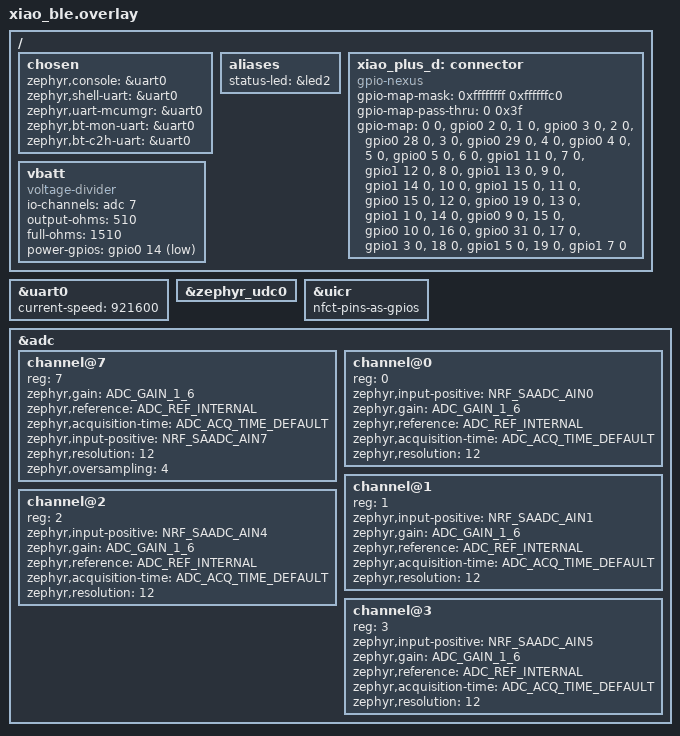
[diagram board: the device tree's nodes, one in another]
/ {
    chosen {
        zephyr,console = &uart0;
        zephyr,shell-uart = &uart0;
        zephyr,uart-mcumgr = &uart0;
        zephyr,bt-mon-uart = &uart0;
        zephyr,bt-c2h-uart = &uart0;
    };

    aliases {
        status-led = &led2;
    };
};

&uart0 {
    current-speed = <921600>;
};

&zephyr_udc0 {
    /delete-node/ board_cdc_acm_uart;
};

&uicr {
    nfct-pins-as-gpios;
};

/ {
    xiao_plus_d: connector {
        compatible = "gpio-nexus";
        #gpio-cells = <2>;
        gpio-map-mask = <0xffffffff 0xffffffc0>;
        gpio-map-pass-thru = <0 0x3f>;
        gpio-map = <0 0 &gpio0 2 0>, /* D0 */
            <1 0 &gpio0 3 0>,        /* D1 */
            <2 0 &gpio0 28 0>,       /* D2 */
            <3 0 &gpio0 29 0>,       /* D3 */
            <4 0 &gpio0 4 0>,        /* D4 */
            <5 0 &gpio0 5 0>,        /* D5 */
            <6 0 &gpio1 11 0>,       /* D6 */
            <7 0 &gpio1 12 0>,       /* D7 */
            <8 0 &gpio1 13 0>,       /* D8 */
            <9 0 &gpio1 14 0>,       /* D9 */
            <10 0 &gpio1 15 0>,      /* D10 */
            <11 0 &gpio0 15 0>,      /* D0.5 */
            <12 0 &gpio0 19 0>,      /* D1.5 */
            <13 0 &gpio1 1 0>,       /* D2.5 */
            <14 0 &gpio0 9 0>,       /* D3.5 */
            <15 0 &gpio0 10 0>,      /* D4.5 */
            <16 0 &gpio0 31 0>,      /* D5.5 */
            <17 0 &gpio1 3 0>,       /* D7.5 */
            <18 0 &gpio1 5 0>,       /* D8.5 */
            <19 0 &gpio1 7 0>;       /* D9.5 */
    };
};

#include <zephyr/dt-bindings/adc/adc.h>
#include <zephyr/dt-bindings/adc/nrf-saadc.h>

/ {
    vbatt {
        compatible = "voltage-divider";
        io-channels = <&adc 7>;
        output-ohms = <510>;
        full-ohms = <1510>;
        power-gpios = <&gpio0 14 (GPIO_ACTIVE_LOW | GPIO_OPEN_DRAIN)>;
    };
};

&adc {
    #address-cells = <1>;
    #size-cells = <0>;

    channel@7 {
        reg = <7>;
        zephyr,gain = "ADC_GAIN_1_6";
        zephyr,reference = "ADC_REF_INTERNAL";
        zephyr,acquisition-time = <ADC_ACQ_TIME_DEFAULT>;
        zephyr,input-positive = <NRF_SAADC_AIN7>;
        zephyr,resolution = <12>;
        zephyr,oversampling = <4>;
    };

    channel@0 {
        reg = <0>;

        /* P0.02 (AIN0) */
        zephyr,input-positive = <NRF_SAADC_AIN0>;

        zephyr,gain = "ADC_GAIN_1_6";
        zephyr,reference = "ADC_REF_INTERNAL";
        zephyr,acquisition-time = <ADC_ACQ_TIME_DEFAULT>;
        zephyr,resolution = <12>;
    };

    channel@1 {
        reg = <1>;

        /* P0.03 (AIN1) */
        zephyr,input-positive = <NRF_SAADC_AIN1>;

        zephyr,gain = "ADC_GAIN_1_6";
        zephyr,reference = "ADC_REF_INTERNAL";
        zephyr,acquisition-time = <ADC_ACQ_TIME_DEFAULT>;
        zephyr,resolution = <12>;
    };

    channel@2 {
        reg = <2>;

        /* D2, P0.28 (AIN4) */
        zephyr,input-positive = <NRF_SAADC_AIN4>;

        zephyr,gain = "ADC_GAIN_1_6";
        zephyr,reference = "ADC_REF_INTERNAL";
        zephyr,acquisition-time = <ADC_ACQ_TIME_DEFAULT>;
        zephyr,resolution = <12>;
    };

    channel@3 {
        reg = <3>;

        /* D3, P0.29 (AIN5) */
        zephyr,input-positive = <NRF_SAADC_AIN5>;

        zephyr,gain = "ADC_GAIN_1_6";
        zephyr,reference = "ADC_REF_INTERNAL";
        zephyr,acquisition-time = <ADC_ACQ_TIME_DEFAULT>;
        zephyr,resolution = <12>;
    };
};

xiao_adc: &adc {};
